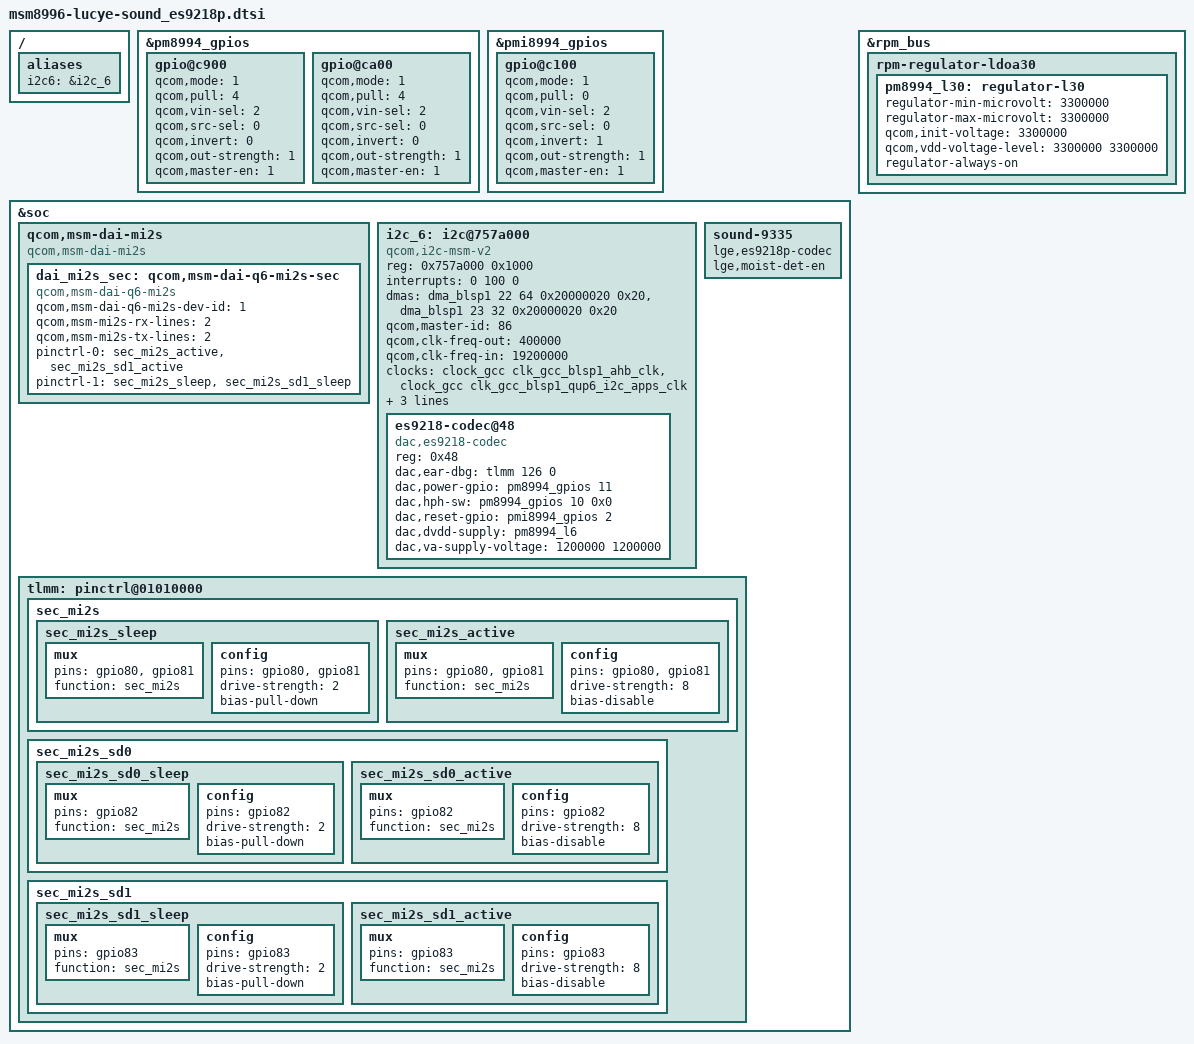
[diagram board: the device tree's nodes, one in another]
/* Copyright (c) 2015, The Linux Foundation. All rights reserved.
 *
 * This program is free software; you can redistribute it and/or modify
 * it under the terms of the GNU General Public License version 2 and
 * only version 2 as published by the Free Software Foundation.
 *
 * This program is distributed in the hope that it will be useful,
 * but WITHOUT ANY WARRANTY; without even the implied warranty of
 * MERCHANTABILITY or FITNESS FOR A PARTICULAR PURPOSE.  See the
 * GNU General Public License for more details.
 */

///////////////////////////////////////////////////////////////////////////////////////
// 
// ESS DAC Sound Setting. It should be included in msm8996-lucye-(operator)-sound.dtsi
//
///////////////////////////////////////////////////////////////////////////////////////

/{
	aliases {
		i2c6 = &i2c_6;
	};
};

/* gpio setting is in dts file. */
&pm8994_gpios {
	gpio@c900 { /* GPIO 10 - NC -> HIFI_MODE2 */
		qcom,mode = <1>;			/* Digital output */
		qcom,pull = <4>;			/* Pull down */
		qcom,vin-sel = <2>;			/* Vin2 */
		qcom,src-sel = <0>;			/* Constant */
		qcom,invert = <0>;			/* Disable Invert */
		qcom,out-strength = <1>;	/* Low */
		qcom,master-en = <1>;		/* Disable GPIO */
		status = "okay";
	};

	gpio@ca00 { /* GPIO 11 - HIFI_LDO_SW */
		qcom,mode = <1>;			/* Digital output */
		qcom,pull = <4>;			/* Pull down */
		qcom,vin-sel = <2>;			/* Vin 2 */
		qcom,src-sel = <0>;			/* Constant */
		qcom,invert = <0>;			/* Invert */
		qcom,out-strength = <1>;	/* Low */
		qcom,master-en = <1>;		/* Enable GPIO */
		status = "okay";
	};
};

&pmi8994_gpios {
	gpio@c100 { /* GPIO 2 - HIFI_RESET_N */
		qcom,mode = <1>;			/* Digital output*/
		qcom,pull = <0>;			/* Pull down 30uA */
		qcom,vin-sel = <2>;			/* VIN2 */
		qcom,src-sel = <0>;			/* Constant */
		qcom,invert = <1>;			/* Enable Invert */
		qcom,out-strength = <1>;	/* Low */
		qcom,master-en = <1>;		/* Enable GPIO */
		status = "okay";
	};
};

&soc {
	qcom,msm-dai-mi2s {
		compatible = "qcom,msm-dai-mi2s";
		dai_mi2s_sec: qcom,msm-dai-q6-mi2s-sec {
			compatible = "qcom,msm-dai-q6-mi2s";
			qcom,msm-dai-q6-mi2s-dev-id = <1>;
			qcom,msm-mi2s-rx-lines = <2>;
			qcom,msm-mi2s-tx-lines = <2>;
			pinctrl-names = "default", "idle";
			pinctrl-0 = <&sec_mi2s_active &sec_mi2s_sd1_active>;
			pinctrl-1 = <&sec_mi2s_sleep &sec_mi2s_sd1_sleep>;
		};	
	};
	
	i2c_6: i2c@757a000 { /* BLSP1 QUP6 */
		compatible = "qcom,i2c-msm-v2";
		#address-cells = <1>;
		#size-cells = <0>;
		reg-names = "qup_phys_addr";
		reg = <0x757a000 0x1000>;
		interrupt-names = "qup_irq";
		interrupts = <0 100 0>;
		dmas = <&dma_blsp1 22 64 0x20000020 0x20>,
				<&dma_blsp1 23 32 0x20000020 0x20>;
		dma-names = "tx", "rx";
		qcom,master-id = <86>;
		qcom,clk-freq-out = <400000>;
		qcom,clk-freq-in  = <19200000>;
		clock-names = "iface_clk", "core_clk";
		clocks = <&clock_gcc clk_gcc_blsp1_ahb_clk>,
			<&clock_gcc clk_gcc_blsp1_qup6_i2c_apps_clk>;
		pinctrl-names = "default", "i2c_active", "i2c_sleep";
		pinctrl-0 = <&i2c_6_default>;
		pinctrl-1 = <&i2c_6_active>;
		pinctrl-2 = <&i2c_6_sleep>;
	};
};

&soc {
	sound-9335 {
		lge,es9218p-codec;
		lge,moist-det-en;
	};
	i2c_6: i2c@757a000 {
		es9218-codec@48 {
			compatible = "dac,es9218-codec";
			status = "okay";
			reg = <0x48>;
			dac,ear-dbg = <&tlmm 126 0>;
			dac,power-gpio = <&pm8994_gpios 11 0x0>;
			dac,hph-sw = <&pm8994_gpios 10 0x0>;
			dac,reset-gpio = <&pmi8994_gpios 2 0x0>;
			dac,dvdd-supply = <&pm8994_l6>;
			dac,va-supply-voltage = <1200000 1200000>;
		};
	};
};

&soc {
	tlmm: pinctrl@01010000 {
    		sec_mi2s {
			sec_mi2s_sleep: sec_mi2s_sleep {
				mux {
					pins = "gpio80", "gpio81";
					function = "sec_mi2s";
				};
				config {
					pins = "gpio80", "gpio81";
					drive-strength = <2>;   /* 2 mA */
					bias-pull-down;         /* PULL DOWN */
				};
			};
			sec_mi2s_active: sec_mi2s_active {
				mux {
					pins = "gpio80", "gpio81";
					function = "sec_mi2s";
				};
				config {
					pins = "gpio80", "gpio81";
					drive-strength = <8>;   /* 8 mA */
					bias-disable;           /* NO PULL */
				};
			};
		};
        
		sec_mi2s_sd0 {
			sec_mi2s_sd0_sleep: sec_mi2s_sd0_sleep {
				mux {
					pins = "gpio82";
					function = "sec_mi2s";
				};
				config {
					pins = "gpio82";
					drive-strength = <2>;   /* 2 mA */
					bias-pull-down;         /* PULL DOWN */
				};
			};
			sec_mi2s_sd0_active: sec_mi2s_sd0_active {
				mux {
					pins = "gpio82";
					function = "sec_mi2s";
				};
				config {
					pins = "gpio82";
					drive-strength = <8>;   /* 8 mA */
					bias-disable;           /* NO PULL */
				};
			};
		};

		sec_mi2s_sd1 {
			sec_mi2s_sd1_sleep: sec_mi2s_sd1_sleep {
				mux {
					pins = "gpio83";
					function = "sec_mi2s";
				};
				config {
					pins = "gpio83";
					drive-strength = <2>;   /* 2 mA */
					bias-pull-down;         /* PULL DOWN */
				};
			};
			sec_mi2s_sd1_active: sec_mi2s_sd1_active {
				mux {
					pins = "gpio83";
					function = "sec_mi2s";
				};
				config {
					pins = "gpio83";
					drive-strength = <8>;   /* 8 mA */
					bias-disable;           /* NO PULL */
				};
			};
		};
	};
};

&rpm_bus {
//Comparator for 2Vrms Hi-Fi
//Enable LDO30A Regulator if ESS Chip is installed
	 rpm-regulator-ldoa30 {
		status = "ok";
		pm8994_l30: regulator-l30 {
				regulator-min-microvolt = <3300000>;
				regulator-max-microvolt = <3300000>;
				qcom,init-voltage = <3300000>;
				qcom,vdd-voltage-level = <3300000 3300000>;
				regulator-always-on;
				status = "okay";
			};
	};
};
